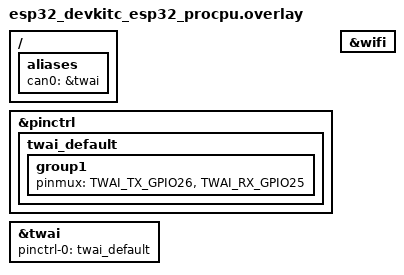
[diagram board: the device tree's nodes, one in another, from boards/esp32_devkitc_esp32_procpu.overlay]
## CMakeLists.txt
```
cmake_minimum_required(VERSION 3.20.0)

find_package(Zephyr REQUIRED HINTS $ENV{ZEPHYR_BASE})

project(gateway_board)

set(GENERATED_DIR ${CMAKE_CURRENT_BINARY_DIR}/generated)

set(GENERATED_C ${GENERATED_DIR}/dummy.c)
set(GENERATED_H ${GENERATED_DIR}/dummy.h)

add_custom_command(
    OUTPUT
        ${GENERATED_C}
        ${GENERATED_H}
    COMMAND ${CMAKE_COMMAND} -E make_directory ${GENERATED_DIR}
    COMMAND python3 -m cantools generate_c_source
            -o ${GENERATED_DIR}
            ${CMAKE_CURRENT_SOURCE_DIR}/../dummy.dbc
    DEPENDS
        ${CMAKE_CURRENT_SOURCE_DIR}/../dummy.dbc
    COMMENT "Generating CAN source files with cantools"
    VERBATIM
)

add_custom_target(generate_can_sources
    DEPENDS
        ${GENERATED_C}
        ${GENERATED_H}
)

file(GLOB APP_SOURCES "src/*.c")

target_sources(app PRIVATE
    ${APP_SOURCES}
    ${GENERATED_C}
)

target_include_directories(app PRIVATE
    inc/
    ${GENERATED_DIR}
)

add_dependencies(app generate_can_sources)
```

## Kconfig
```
config WATCHDOG_TIMEOUT
    int "Set time after which watchdog resets the board, in ms"
    range 60000 300000
    default 120000
    help
        Watchdog is used as last line of defense and recovery if gateway board
        hangs on unknown error. Range 1 min - 5 min.

config WIFI_SSID
    string "Name of the target WiFi network"
    help
        Set the name of the WiFi network that gateway board is supposed to connect to.

config WIFI_PSK
    string "Password of the target WiFi network"
    help
        Set the password that gateway board will use to authenticate itself to the
        target WiFi network.

config MQTT_CLIENT_NAME
    string "Name that gateway board will use to introduce itself to MQTT broker"

config MQTT_BROKER_ADDRESS
    string "URL adress of MQTT broker used by gateway board"
    
config MQTT_BROKER_PORT
    int "Port of MQTT broker used by gateway board"

config MQTT_PUBLISH_TOPIC
    string "MQTT topic that gateway board will publish to"

config MQTT_SUBSCRIBE_TOPIC
    string "MQTT topic that gateway board will subscribe to"

config MQTT_MESSAGE_RX_BUFFER_SIZE
    int "Set size of MQTT buffer RX size."
    range 128 65536
    default 8192
    help
        This buffer is used to store fragments of new user application. The bigger, the more
        efficient flashing process will be. Has to be a multiple of 8.

config MQTT_MESSAGE_TX_BUFFER_SIZE
    int "Set size of MQTT buffer RX size."
    range 128 1024
    default 128
    help
        Used to store debug messages before publishing them. Should be minimum of 128.

source "Kconfig.zephyr"
```

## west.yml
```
manifest:
  version: 1.0

  projects:
    - name: zephyr
      url: https://github.com/zephyrproject-rtos/zephyr
      revision: v4.5.0
      import:
        name-allowlist:
          - cmsis_6
          - hal_nxp
          - hal_stm32
          - hal_nordic
        path-prefix: deps
```

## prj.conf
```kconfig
# Logger module
CONFIG_LOG=y
CONFIG_LOG_MAX_LEVEL=3

# Watchdog
CONFIG_WATCHDOG=y

# CAN
CONFIG_CAN=y

# Memory
CONFIG_MAIN_STACK_SIZE=5200
CONFIG_NET_TX_STACK_SIZE=2048
CONFIG_NET_RX_STACK_SIZE=2048

CONFIG_NET_PKT_RX_COUNT=10
CONFIG_NET_PKT_TX_COUNT=10
CONFIG_NET_BUF_RX_COUNT=20
CONFIG_NET_BUF_TX_COUNT=20
CONFIG_NET_MAX_CONTEXTS=10
CONFIG_INIT_STACKS=y

# Networking
CONFIG_NETWORKING=y
CONFIG_POSIX_API=y
CONFIG_NET_DHCPV4=y
CONFIG_DNS_RESOLVER=y
CONFIG_NET_TCP=y
CONFIG_NET_IPV4=y
CONFIG_NET_IPV6=n

# WiFi
CONFIG_WIFI=y

# MQTT
CONFIG_MQTT_LIB=y
CONFIG_MQTT_CLEAN_SESSION=y

# CRC
CONFIG_CRC=y

# User configurable
CONFIG_WIFI_SSID="Ryszard"
CONFIG_WIFI_PSK="jestnatrello"
CONFIG_MQTT_CLIENT_NAME="zephyr_gateway_board_client"
CONFIG_MQTT_BROKER_ADDRESS="broker.hivemq.com"
CONFIG_MQTT_BROKER_PORT=1883
CONFIG_MQTT_PUBLISH_TOPIC="system/gateway_board/publish/state"
CONFIG_MQTT_SUBSCRIBE_TOPIC="system/gateway_board/subscribe/new_app"

# Set only if different than default
#CONFIG_WATCHDOG_TIMEOUT=
#CONFIG_MQTT_MESSAGE_RX_BUFFER_SIZE=
#CONFIG_MQTT_MESSAGE_TX_BUFFER_SIZE=
```

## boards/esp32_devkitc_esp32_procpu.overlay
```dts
/ {
    aliases {
        can0 = &twai;
    };
};

&pinctrl {
    twai_default: twai_default {
        group1 {
            pinmux = <TWAI_TX_GPIO26>, <TWAI_RX_GPIO25>;
        };
    };
};

&twai {
    status = "okay";
    pinctrl-0 = <&twai_default>;
    pinctrl-names = "default";
};

&wifi {
    status = "okay";
};
```

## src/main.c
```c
#include "main.h"
#include "can-utils.h"
#include "wifi-utils.h"
#include "watchdog-utils.h"

#include <zephyr/kernel.h>
#include <zephyr/drivers/gpio.h>
#include <zephyr/logging/log.h>

LOG_MODULE_REGISTER(Main, LOG_LEVEL_DBG);

int main()
{
    int ret;

    ret = setup_watchdog();
    if (ret < 0) {
        LOG_ERR("Watchdog setup failed");
        return 1;
    }

    init_wifi();

    ret = setup_can_device();
    if (ret < 0) {
        LOG_ERR("Failed to setup can device, error %d", ret);
        return 1;
    }

    LOG_INF("Setup complete, enter main processing loop");

    while (true) {
        if (!atomic_get(&wifi_ready)) {
            LOG_INF("WiFi setup in progress...");

            ret = setup_wifi();
            if (ret < 0) {
                LOG_ERR("WiFi connect failed");
                k_sleep(K_SECONDS(WAIT_ON_ERROR_TIME));
            }

            continue;
        }

        if (!atomic_get(&mqtt_ready)) {
            LOG_INF("MQTT setup in progress...");

            ret = setup_mqtt();
            if (ret < 0) {
                LOG_ERR("MQTT setup failed");
                k_sleep(K_SECONDS(WAIT_ON_ERROR_TIME));
            }

            continue;
        }

        ret = poll_mqtt();
        if (ret != 0) {
            LOG_ERR("Failed to poll MQTT socket, error %d", ret);
            k_sleep(K_SECONDS(WAIT_ON_ERROR_TIME));
            continue;
        }

        ret = feed_watchdog();
        if (ret != 0) {
            LOG_ERR("Failed to feed watchdog, error %d", ret);
            k_sleep(K_SECONDS(WAIT_ON_ERROR_TIME));
            continue;
        } else {
            LOG_DBG("Watchdog fed");
        }
    }

    return 0;
}
```

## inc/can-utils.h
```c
#ifndef __CAN_UTILS_H
#define __CAN_UTILS_H

#include <zephyr/device.h>

// Max payload size of standard CAN frame
#define CAN_FRAME_MAX_PAYLOAD 8

// Timeout for accessing CAN TX mailbox
#define CAN_TX_MAILBOX_TIMEOUT 5

// Timeout waiting for CAN control message back
#define CAN_CTRL_MSG_TIMEOUT 10

// Accept frame with any ID
#define CAN_FILTER_MASK 0x0

// No flags, CAN working with standard 11-bit id frames
#define CAN_FILTER_FLAGS 0x0
#define CAN_FRAME_FLAGS  0x0

// Command messages used in payload of
// bootloader control messages
#define BOOTLOADER_COMMAND_START  0
#define BOOTLOADER_COMMAND_SETUP  1
#define BOOTLOADER_COMMAND_PING   2
#define BOOTLOADER_COMMAND_FINISH 3
#define BOOTLOADER_COMMAND_ACK    4
#define BOOTLOADER_COMMAND_ABORT  5

// Configure CAN filter and start CAN
int setup_can_device();

// Send given number of bytes from data in CAN frame
int send_can_frame(int id, uint8_t *data, size_t size);

// Send control frame to node
int send_control_frame(int ctrl_frame_id, uint8_t command, uint32_t *crc);

// Send control frame to node and wait for control frame back
int send_wait_control_frame(int ctrl_frame_id, uint8_t command, uint32_t *crc);

#endif /* __CAN_UTILS_H */
```

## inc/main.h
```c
#ifndef __MAIN_H
#define __MAIN_H

// Wait for 1s before retrying
#define WAIT_ON_ERROR_TIME 1

#endif /* __MAIN_H */
```

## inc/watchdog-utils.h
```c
#ifndef __WATCHDOG_UTILS_H
#define __WATCHDOG_UTILS_H

// First point of interaction with this module,
// called once to setup watchdog
int setup_watchdog();

// Call periodically to prevent board reset
int feed_watchdog();

#endif /* __WATCHDOG_UTILS_H */
```

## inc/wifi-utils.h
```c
#ifndef __WIFI_UTILS_H
#define __WIFI_UTILS_H

#include <zephyr/kernel.h>
#include <zephyr/sys/atomic.h>

#define WIFI_EVENTS (NET_EVENT_WIFI_CONNECT_RESULT | NET_EVENT_WIFI_DISCONNECT_RESULT)

#define WIFI_CONNECT_TIMEOUT 30
#define MQTT_CONNECT_TIMEOUT 30

// Device connected to WiFi
// Declared in wifi-utils.h,
// defined in wifi-utils.c
extern atomic_t wifi_ready;

// Connection to MQTT broker established
// Declared in wifi-utils.h,
// defined in wifi-utils.c
extern atomic_t mqtt_ready;

// Initialize WiFi callbacks
void init_wifi();

// Establish WiFi connection, blocking
int setup_wifi();

// Establish MQTT connection, blocking
int setup_mqtt();

// Poll MQTT socket, must be called at least
// once to get MQTT connection
int poll_mqtt();

#endif /* __WIFI_UTILS_H */
```

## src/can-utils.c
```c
#include "can-utils.h"

#include <zephyr/kernel.h>
#include <zephyr/drivers/can.h>
#include <zephyr/logging/log.h>
#include <zephyr/sys/byteorder.h>

LOG_MODULE_REGISTER(CanUtils, LOG_LEVEL_DBG);

K_SEM_DEFINE(can_ctrl_frame_sem, 0, 1);

static const struct device *can_dev = DEVICE_DT_GET(DT_ALIAS(can0));
static volatile uint32_t current_can_control_frame = UINT32_MAX;

static void rx_callback(const struct device *dev, struct can_frame *frame, void *user_data) 
{
    LOG_INF("Received CAN frame with ID 0x%02X, comparing with global ID 0x%02X", frame->id, current_can_control_frame);

    if (frame->id != current_can_control_frame) {
        return;
    }

    if (frame->dlc != 1) {
        return;
    }

    if (frame->data[0] != BOOTLOADER_COMMAND_ACK) {
        return;
    }

    k_sem_give(&can_ctrl_frame_sem);
}

int setup_can_device()
{
    if (!device_is_ready(can_dev)) {
        LOG_ERR("CAN device not ready");
        return 1;
    }

    // Setup CAN filter (accept every frame)
    struct can_filter filter = {
        .id = 0,
        .mask = CAN_FILTER_MASK,
        .flags = CAN_FILTER_FLAGS
    };

    // Add filter and RX callback
    int ret = can_add_rx_filter(can_dev, &rx_callback, NULL, &filter);
    if (ret < 0) {
        LOG_ERR("Failed to set CAN filter, error %d", ret);
        return ret;
    }

    // Start CAN device
    return can_start(can_dev);
}

int send_can_frame(int id, uint8_t *data, size_t size)
{
    // Verify data size
    if (!(0 <= size && size <= 8)) {
        LOG_ERR("Incorrect frame size, error %d", size);
        return 1;
    }

    // Pack data into CAN frame
    struct can_frame frame = {
        .id = id,
        .flags = CAN_FRAME_FLAGS,
        .dlc = size
    };

    memcpy(frame.data, data, size);

    // Send CAN frame 
    return can_send(can_dev, &frame, K_SECONDS(CAN_TX_MAILBOX_TIMEOUT), NULL, NULL);
}

int send_control_frame(int ctrl_frame_id, uint8_t command, uint32_t *crc)
{
    if (crc == NULL) {
        return send_can_frame(ctrl_frame_id, &command, sizeof(uint8_t));
    } else {
        uint32_t crc_le = sys_cpu_to_le32(*crc);
        uint8_t crc_bytes[4] = sys_uint32_to_array(crc_le);
        uint8_t payload[5] = {command, crc_bytes[0], crc_bytes[1], crc_bytes[2], crc_bytes[3]};
        return send_can_frame(ctrl_frame_id, payload, sizeof(payload));
    }
}

int send_wait_control_frame(int ctrl_frame_id, uint8_t command, uint32_t *crc)
{
    // Set global CAN CTRL frame ID
    current_can_control_frame = ctrl_frame_id;

    // Send CAN CTRL frame
    int ret = send_control_frame(ctrl_frame_id, command, crc);
    if (ret != 0) {
        LOG_ERR("Failed to send CTRL frame to node, error %d", ret);
        return ret;
    }

    // Wait for CAN CTRL frame back
    ret = k_sem_take(&can_ctrl_frame_sem, K_SECONDS(CAN_CTRL_MSG_TIMEOUT));
    if (ret != 0) {
        LOG_ERR("Failed to receive ACK message from bootloader, node in unknown state, error %d", ret);
    } else {
        LOG_INF("Received bootloader ACK message");
    }

    // Reset global state
    current_can_control_frame = -1;

    return ret;
}
```

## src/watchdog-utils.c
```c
#include <zephyr/kernel.h>
#include <zephyr/drivers/watchdog.h>
#include <zephyr/logging/log.h>

LOG_MODULE_REGISTER(WatchdogUtils, LOG_LEVEL_DBG);

static const struct device *wdt = DEVICE_DT_GET(DT_ALIAS(watchdog0));
static int channel_id = -1;

int setup_watchdog()
{
    int ret;

    if (!device_is_ready(wdt)) {
        LOG_ERR("Watchdog not ready!");
        return -1;
    }

    const struct wdt_timeout_cfg cfg = {
        .window.min = 0,
        .window.max = CONFIG_WATCHDOG_TIMEOUT,
        .flags = WDT_FLAG_RESET_SOC,
        .callback = NULL
    };

    ret = wdt_install_timeout(wdt, &cfg);
    if (ret < 0) {
        LOG_ERR("Installing watchdog timeout failed, error %d", ret);
        return ret;
    }

    channel_id = ret;

    return wdt_setup(wdt, WDT_FLAG_RESET_SOC);
}

int feed_watchdog()
{
    return wdt_feed(wdt, channel_id);
}
```

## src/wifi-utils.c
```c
#include "wifi-utils.h"
#include "can-utils.h"
#include "watchdog-utils.h"

#include <zephyr/net/net_if.h>
#include <zephyr/net/net_mgmt.h>
#include <zephyr/net/wifi.h>
#include <zephyr/net/wifi_mgmt.h>
#include <zephyr/net/mqtt.h>
#include <zephyr/net/socket.h>
#include <zephyr/net/net_ip.h>
#include <zephyr/sys/crc.h>

#include <zephyr/logging/log.h>

LOG_MODULE_REGISTER(WifiUtils, LOG_LEVEL_DBG);

/* Semaphores for internal state signaling */
K_SEM_DEFINE(wifi_ready_flag, 0, 1);
K_SEM_DEFINE(mqtt_ready_flag, 0, 1);

/* Atomic flags for state machine from main.c */
atomic_t wifi_ready = ATOMIC_INIT(0x0);
atomic_t mqtt_ready = ATOMIC_INIT(0x0);

/* MQTT buffers */
static uint8_t rx_buffer[CONFIG_MQTT_MESSAGE_RX_BUFFER_SIZE] = { 0x0 };
static uint8_t tx_buffer[CONFIG_MQTT_MESSAGE_TX_BUFFER_SIZE] = { 0x0 };

/* WiFi and MQTT internal structs */
static struct net_mgmt_event_callback wifi_callback;
static struct sockaddr_in broker;
static struct mqtt_client client;
static struct zsock_pollfd fds;

/* WiFi internal functions */
static void update_state_on_wifi_connect();
static void update_state_on_wifi_disconnect();
static void fill_wifi_connect_params(struct wifi_connect_req_params *params);
static void wifi_handler(struct net_mgmt_event_callback *cb, uint64_t event, struct net_if *iface);

/* MQTT internal functions */
static void update_state_on_mqtt_connect();
static void update_state_on_mqtt_disconnect();
static int subscribe();
static int server_resolve();
static void fill_mqtt_client_params();
static void mqtt_handler(struct mqtt_client *client, const struct mqtt_evt *evt);

/* CAN internal functions */
static int pad_rx_buffer(uint32_t bytes_in_buffer);
static int send_rx_buffer(int firmware_frame_id, int rx_buffer_current_size);
static int send_rx_buffer_protected(int control_frame_id, int firmware_frame_id, int rx_buffer_current_size);
static int flash_new_firmware(struct mqtt_client *client, const struct mqtt_evt *evt);
static int bootloader_start(int control_frame_id);
static int bootloader_setup(int control_frame_id);
static int bootloader_ping(int control_frame_id);
static int bootloader_stop(int control_frame_id, uint32_t crc);
static int bootloader_abort(int control_frame_id);

/* ***************** */
/* MODULE PUBLIC API */
/* ***************** */

/* WiFi init, first point of interaction with this module */
void init_wifi()
{
    net_mgmt_init_event_callback(&wifi_callback, wifi_handler, WIFI_EVENTS);
    net_mgmt_add_event_callback(&wifi_callback);
}

/* WiFi setup, second point of interaction with this module */
int setup_wifi()
{
    struct net_if *iface = net_if_get_default();
    if (iface == NULL) {
        LOG_ERR("Net interface not configured");
        return 1;
    }

    struct wifi_connect_req_params wifi_params;

    fill_wifi_connect_params(&wifi_params);

    int ret = net_mgmt(NET_REQUEST_WIFI_CONNECT, iface, &wifi_params, sizeof(wifi_params));
    if (ret == -EALREADY) {
        LOG_INF("WiFi connecting already in progress");
    } else if (ret < 0) {
        LOG_ERR("net_mgmt returned error %d", ret);
        return ret;
    } else {
        LOG_INF("Params setup, waiting for WiFi connection");
    }

    return k_sem_take(&wifi_ready_flag, K_SECONDS(WIFI_CONNECT_TIMEOUT));
}

/* MQTT setup, third point of interaction with this module */
int setup_mqtt()
{
    mqtt_client_init(&client);

    int err = server_resolve();
    if (err != 0) {
        LOG_ERR("Failed to resolve broker hostname");
        return err;
    }

    fill_mqtt_client_params();

    err = mqtt_connect(&client);
    if (err != 0) {
        LOG_ERR("Failed to call mqtt_connect, error %d", err);
        return err;
    }

    fds.fd = client.transport.tcp.sock;
    fds.events = ZSOCK_POLLIN;

    err = poll_mqtt();
    if (err != 0) {
        LOG_ERR("Failed to poll MQTT socket, error %d", err);
        return err;
    }

    err = k_sem_take(&mqtt_ready_flag, K_SECONDS(MQTT_CONNECT_TIMEOUT));
    if (err != 0) {
        zsock_close(client.transport.tcp.sock);
        mqtt_disconnect(&client, NULL);
    }

    return err;
}

/* MQTT poll, should be called periodically */
int poll_mqtt()
{
    int err = zsock_poll(&fds, 1, mqtt_keepalive_time_left(&client));
    if (err < 0) {
        LOG_ERR("Error when calling poll, error %d", err);
        return err;
    }

    err = mqtt_live(&client);
    if (err != 0 && err != -EAGAIN) {
        LOG_ERR("Error when calling mqtt_live, error %d", err);
        return err;
    }

    if ((fds.revents & ZSOCK_POLLIN) == ZSOCK_POLLIN) {
        err = mqtt_input(&client);
        if (err) {
            LOG_ERR("Error when calling mqtt_input, error %d", err);
            return err;
        }

        fds.revents = 0;
    }

    return 0;
}

/* ****************** */
/* INTERNAL FUNCTIONS */
/* ****************** */

/* ----------------------- */
/* Internal WiFi Functions */
/* ----------------------- */

static void update_state_on_wifi_connect()
{
    k_sem_give(&wifi_ready_flag);
    atomic_set(&wifi_ready, 1);
}

static void update_state_on_wifi_disconnect()
{
    k_sem_take(&wifi_ready_flag, K_NO_WAIT);
    k_sem_take(&mqtt_ready_flag, K_NO_WAIT);
    atomic_set(&wifi_ready, 0);
    atomic_set(&mqtt_ready, 0);
}

static void fill_wifi_connect_params(struct wifi_connect_req_params *params)
{
    memset(params, 0, sizeof(struct wifi_connect_req_params));

    params->ssid = CONFIG_WIFI_SSID;
    params->ssid_length = strlen(CONFIG_WIFI_SSID);

    params->psk = CONFIG_WIFI_PSK;
    params->psk_length = strlen(CONFIG_WIFI_PSK);

    params->band = 0;
    params->security = WIFI_SECURITY_TYPE_PSK;
}

static void wifi_handler(struct net_mgmt_event_callback *cb, uint64_t event, struct net_if *iface)
{
    switch (event) {
        case NET_EVENT_WIFI_CONNECT_RESULT:
            struct wifi_status *received_status = (struct wifi_status *)(cb->info);
            if (received_status->conn_status == WIFI_STATUS_CONN_SUCCESS) {
                update_state_on_wifi_connect();
                LOG_INF("Connected to %s", CONFIG_WIFI_SSID);
            } else {
                LOG_INF("Not connected, error: %d", received_status->conn_status);
            }
            break;

        case NET_EVENT_WIFI_DISCONNECT_RESULT:
            update_state_on_wifi_disconnect();

            int ret = mqtt_disconnect(&client, NULL);
            if (ret < 0) {
                LOG_WRN("MQTT disconnect failed, error %d", ret);
            } else {
                LOG_INF("MQTT disconnected");
            }

            LOG_INF("Disconnected, error: %d", *((int32_t *)(cb->info)));
            break;

        default:
            LOG_WRN("Unknown WiFi event reached handler %llu", event);
            break;
    }
}

/* ----------------------- */
/* Internal MQTT Functions */
/* ----------------------- */

static void update_state_on_mqtt_connect()
{
    k_sem_give(&mqtt_ready_flag);
    atomic_set(&mqtt_ready, 1);
}

static void update_state_on_mqtt_disconnect()
{
    k_sem_take(&mqtt_ready_flag, K_NO_WAIT);
    atomic_set(&mqtt_ready, 0);
}

static int subscribe()
{
    struct mqtt_topic sub_topic = {
        .topic = {
            .utf8 = CONFIG_MQTT_SUBSCRIBE_TOPIC,
            .size = strlen(CONFIG_MQTT_SUBSCRIBE_TOPIC)
        },
        .qos = MQTT_QOS_0_AT_MOST_ONCE
    };

    const struct mqtt_subscription_list sub_list = {
        .list = &sub_topic,
        .list_count = 1,
        .message_id = 6767
    };

    LOG_INF("Subscribing to topic %s", CONFIG_MQTT_SUBSCRIBE_TOPIC);
    return mqtt_subscribe(&client, &sub_list);
}

static void fill_mqtt_client_params()
{
    client.broker = &broker;
    client.evt_cb = mqtt_handler;
    client.client_id.utf8 = CONFIG_MQTT_CLIENT_NAME;
    client.client_id.size = strlen(CONFIG_MQTT_CLIENT_NAME);
    client.password = NULL;
    client.user_name = NULL;
    client.protocol_version = MQTT_VERSION_3_1_1;

    client.rx_buf = rx_buffer;
    client.rx_buf_size = sizeof(rx_buffer);
    client.tx_buf = tx_buffer;
    client.tx_buf_size = sizeof(tx_buffer);

    client.transport.type = MQTT_TRANSPORT_NON_SECURE;
}

static int server_resolve()
{
    int err;

    struct zsock_addrinfo *result;
    struct zsock_addrinfo hints = {
        .ai_family = AF_INET,
        .ai_socktype = SOCK_STREAM
    };

    err = zsock_getaddrinfo(CONFIG_MQTT_BROKER_ADDRESS, NULL, &hints, &result);
    if (err) {
        LOG_ERR("Failed to get address info of %s", CONFIG_MQTT_BROKER_ADDRESS);
        return err;
    }

    if (result == NULL) {
        LOG_ERR("Address not found");
        return -ENOENT;
    }

    broker.sin_family = AF_INET;
    broker.sin_port = htons(CONFIG_MQTT_BROKER_PORT);
    broker.sin_addr.s_addr = ((struct sockaddr_in *)result->ai_addr)->sin_addr.s_addr;

    char addr_str[NET_IPV4_ADDR_LEN];
    net_addr_ntop(AF_INET, &broker.sin_addr, addr_str, sizeof(addr_str));

    LOG_INF("%s resolved as %s", CONFIG_MQTT_BROKER_ADDRESS, addr_str);

    zsock_freeaddrinfo(result);

    return err;
}

static int consume_payload_on_error(struct mqtt_client *client)
{
    LOG_INF("Consuming payload due to error");

    int read = 1;
    while (read > 0) {
        read = mqtt_read_publish_payload(client, rx_buffer, CONFIG_MQTT_MESSAGE_RX_BUFFER_SIZE);
        
        if (read == -EAGAIN) {
            read = 1;
            continue;
        } else if (read < 0) {
            LOG_ERR("Error while consuming payload, error %d", read);
            return read;
        }

        memset(rx_buffer, 0, CONFIG_MQTT_MESSAGE_RX_BUFFER_SIZE);
    }

    return read;
}

static void mqtt_handler(struct mqtt_client *client, const struct mqtt_evt *evt)
{
    switch (evt->type) {
        case MQTT_EVT_CONNACK:
            if (evt->result != 0) {
                LOG_ERR("Unable to connect to broker, error %d", evt->result);
                break;
            }

            subscribe();
            update_state_on_mqtt_connect();
            LOG_INF("MQTT connected");
            break;

        case MQTT_EVT_DISCONNECT:
            update_state_on_mqtt_disconnect();
            LOG_INF("MQTT disconnected");
            break;

        case MQTT_EVT_PUBLISH:
            LOG_INF("Received message on topic %s", evt->param.publish.message.topic.topic.utf8);

            int err = flash_new_firmware(client, evt);
            if (err) {
                LOG_ERR("Failed to flash new application, error %d", err);
                err = consume_payload_on_error(client);
                if (err) {
                    LOG_ERR("MQTT payload failed to be consumed, error %d", err);
                }
            }
            break;

        case MQTT_EVT_SUBACK:
        case MQTT_EVT_PINGRESP:
            break;
        
        default:
            LOG_WRN("Unknown MQTT event, %d", evt->type);
            break;
    }
}

/* ---------------------- */
/* Internal CAN functions */
/* ---------------------- */

static int pad_rx_buffer(uint32_t bytes_in_buffer)
{
    uint32_t remainder = bytes_in_buffer % CAN_FRAME_MAX_PAYLOAD;
    
    // No padding required
    if (remainder == 0) {
        return bytes_in_buffer;
    }

    uint32_t required_padding = CAN_FRAME_MAX_PAYLOAD - remainder;

    memset(rx_buffer + bytes_in_buffer, 0xFF, required_padding);

    return bytes_in_buffer + required_padding;
}

static int send_rx_buffer(int firmware_frame_id, int rx_buffer_current_size)
{
    LOG_INF("Start sending CAN RX buffer");

    int ret, idx = 0;

    // Go through user_application_buffer and send
    // 8-byte fragments via CAN
    while (idx + CAN_FRAME_MAX_PAYLOAD <= rx_buffer_current_size) {

        ret = send_can_frame(firmware_frame_id, rx_buffer + idx, CAN_FRAME_MAX_PAYLOAD);
        if (ret < 0) {
            LOG_ERR("Failed to send CAN frame, error %d", ret);
            return ret;
        }
        
        LOG_DBG("Sent (%d / %d) [ %02x %02x %02x %02x %02x %02x %02x %02x ]",
                idx + 8, rx_buffer_current_size,
                rx_buffer[idx],     rx_buffer[idx + 1],
                rx_buffer[idx + 2], rx_buffer[idx + 3],
                rx_buffer[idx + 4], rx_buffer[idx + 5],
                rx_buffer[idx + 6], rx_buffer[idx + 7]);

        idx += CAN_FRAME_MAX_PAYLOAD;
    }

    // If there are bytes left, indicate error. This should not happen
    // due to padding buffer to a multiple of 8.
    if (rx_buffer_current_size - idx > 0) {
        LOG_ERR("Number of data in buffer not divisible by 8!");
        return -1;
    }
    
    LOG_INF("Sending of CAN RX buffer succeeded");
    
    return 0;
}

static int send_rx_buffer_protected(int control_frame_id, int firmware_frame_id, int rx_buffer_current_size)
{
    int err = send_rx_buffer(firmware_frame_id, rx_buffer_current_size);
    if (err) {
        LOG_ERR("Failed to send firmware, aborting. Error %d", err);
        
        // If continuing flashing is not possible, try to recover to previous app
        return bootloader_abort(control_frame_id);
    }

    return 0;
}

static int bootloader_start(int control_frame_id)
{
    int ret = send_wait_control_frame(control_frame_id, BOOTLOADER_COMMAND_START, NULL);
    if (ret != 0) {
        LOG_ERR("Failed to start bootloader, error %d", ret);
    }

    return ret;
}

static int bootloader_setup(int control_frame_id)
{
    int ret = send_wait_control_frame(control_frame_id, BOOTLOADER_COMMAND_SETUP, NULL);
    if (ret != 0) {
        LOG_ERR("Failed to setup bootloader, error %d", ret);
    }

    return ret;
}

static int bootloader_ping(int control_frame_id)
{
    int ret = send_control_frame(control_frame_id, BOOTLOADER_COMMAND_PING, NULL);
    if (ret != 0) {
        LOG_ERR("Failed to ping bootloader, error %d", ret);
    }

    return ret;
}

static int bootloader_stop(int control_frame_id, uint32_t crc)
{
    int ret = send_wait_control_frame(control_frame_id, BOOTLOADER_COMMAND_FINISH, &crc);
    if (ret != 0) {
        LOG_ERR("Failed to stop bootloader, node left in unknown state, error %d", ret);
    }

    return ret;
}

static int bootloader_abort(int control_frame_id)
{
    int ret = send_wait_control_frame(control_frame_id, BOOTLOADER_COMMAND_ABORT, NULL);
    if (ret != 0) {
        LOG_ERR("Failed to abort bootloader, node left in unknown state, error %d", ret);
    }

    return ret;
}

static int flash_new_firmware(struct mqtt_client *client, const struct mqtt_evt *evt)
{
    int ret;
    memset(rx_buffer, 0, CONFIG_MQTT_MESSAGE_RX_BUFFER_SIZE);

    uint32_t flashing_start = k_uptime_get_32();

    // How many bytes were read to buffer
    uint32_t buffer_read = 0;
    // How many bytes were read from payload
    uint32_t payload_read = 0;
    // Total payload length
    uint32_t payload_len = evt->param.publish.message.payload.len;
    // CRC16 of the payload
    uint32_t crc = 0;

    LOG_INF("Incoming payload size: %d", payload_len);

    // First 2 bytes of MQTT payload are reserved for Control Frame ID
    int control_frame_id = 0;
    ret = mqtt_read_publish_payload(client, &control_frame_id, 2);
    if (ret != 2) {
        LOG_ERR("Failed to read Control Frame ID, malformed MQTT payload, error %d", ret);
        return ret;
    }
    payload_read += ret;

    // Next 2 bytes of MQTT payload are reserved for Firmware Frame ID
    int firmware_frame_id = 0;
    ret = mqtt_read_publish_payload(client, &firmware_frame_id, 2);
    if (ret != 2) {
        LOG_ERR("Failed to read Firmware Frame ID, malformed MQTT payload, error %d", ret);
        return ret;
    }
    payload_read += ret;

    LOG_INF("CAN frames read - [0x%02X] [0x%02X]", control_frame_id, firmware_frame_id);
    LOG_INF("Proceeding with firmware flashing");

    // Make current app jump to bootloader
    ret = bootloader_start(control_frame_id);
    if (ret != 0) {
        return ret;
    }

    // Request bootloader setup (erase Flash slot)
    ret = bootloader_setup(control_frame_id);
    if (ret != 0) {
        return bootloader_abort(control_frame_id);
    }

    // Process payload in a loop
    while (payload_read < payload_len) {
        int n = mqtt_read_publish_payload(client, rx_buffer + buffer_read,
                                          CONFIG_MQTT_MESSAGE_RX_BUFFER_SIZE - buffer_read);
        if (n == -EAGAIN) {
            k_sleep(K_SECONDS(1));
            continue;
        } else if (n < 0) {
            LOG_ERR("Failed to call mqtt_read_publish_payload, error %d", n);
            break;
        }

        payload_read += n;
        buffer_read += n;

        LOG_INF("Read MQTT payload (%d / %d), RX buffer (%d / %d)",
                payload_read, payload_len,
                buffer_read, CONFIG_MQTT_MESSAGE_RX_BUFFER_SIZE);

        // MQTT read depends on connection speed and may be time consuming,
        // ping bootloader to reset its internal timeout handling.
        ret = bootloader_ping(control_frame_id);
        if (ret < 0) {
            return bootloader_abort(control_frame_id);
        }

        // Feed watchdog during time-consuming firmware flashing
        ret = feed_watchdog();
        if (ret < 0) {
            LOG_ERR("Failed to feed watchdog");
        } else {
            LOG_DBG("Watchdog fed");
        }

        // If buffer is full, send it to bootloader
        if (buffer_read == CONFIG_MQTT_MESSAGE_RX_BUFFER_SIZE) {
            ret = send_rx_buffer_protected(control_frame_id, firmware_frame_id, CONFIG_MQTT_MESSAGE_RX_BUFFER_SIZE);
            if (ret) {
                LOG_ERR("Flashing CAN RX buffer failed, node left in unknown state, error %d", ret);
                return ret;
            }

            // Feed the chunk in buffer to CRC16
            crc = crc32_ieee_update(crc, rx_buffer, CONFIG_MQTT_MESSAGE_RX_BUFFER_SIZE);

            // Reset buffer state
            buffer_read = 0;
            memset(rx_buffer, 0, CONFIG_MQTT_MESSAGE_RX_BUFFER_SIZE);
        }
    }

    // If all of payload was read, bytes remaining in buffer have to be sent
    if (payload_read == payload_len) {
        LOG_INF("Received full firmware image: %d bytes", payload_read);

        // The number of remaining bytes might not be a multiple of 8
        // so we pad the buffer.
        buffer_read = pad_rx_buffer(buffer_read);

        ret = send_rx_buffer_protected(control_frame_id, firmware_frame_id, buffer_read);
        if (ret) {
            LOG_ERR("Flashing CAN RX buffer failed, node left in unknown state, error %d", ret);
            return ret;
        }

        crc = crc32_ieee_update(crc, rx_buffer, buffer_read);
        LOG_INF("Calculated payload CRC32: 0x%08X", crc);

        // Reset buffer state
        buffer_read = 0;
        memset(rx_buffer, 0, CONFIG_MQTT_MESSAGE_RX_BUFFER_SIZE);

        LOG_INF("Flashing took %u ms", k_uptime_get_32() - flashing_start);

        // Stop bootloader, jump to newly flashed app
        return bootloader_stop(control_frame_id, crc);
    } else {
        LOG_ERR("Failed to read full payload, trying to abort");
        return bootloader_abort(control_frame_id);
    }
}
```
